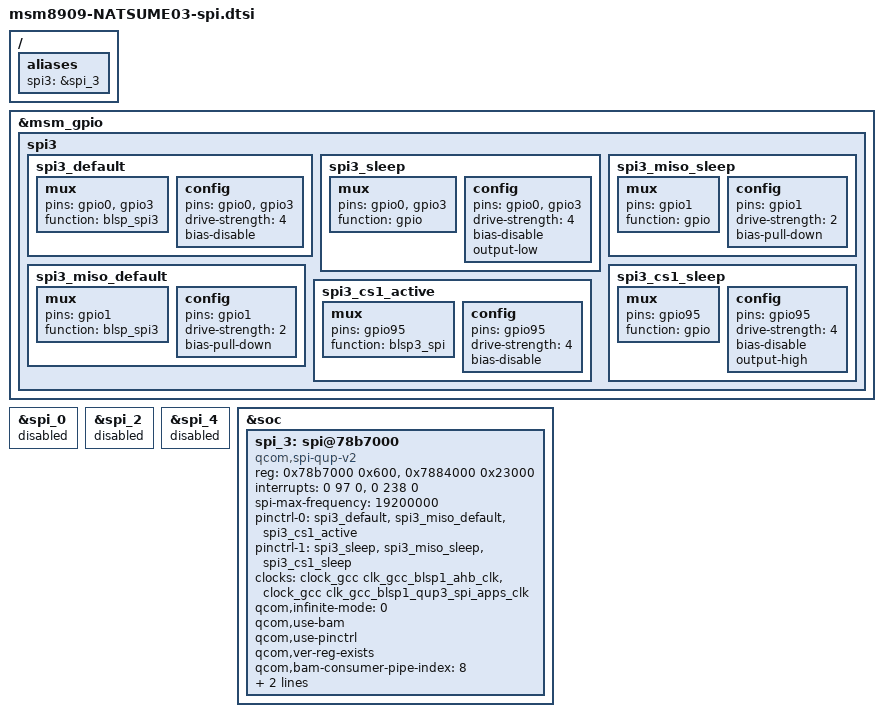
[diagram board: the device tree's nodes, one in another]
/*
 * This software is contributed or developed by KYOCERA Corporation.
 * (C) 2019 KYOCERA Corporation
 *
 * This program is free software; you can redistribute it and/or modify
 * it under the terms of the GNU General Public License version 2 and
 * only version 2 as published by the Free Software Foundation.
 *
 * This program is distributed in the hope that it will be useful,
 * but WITHOUT ANY WARRANTY; without even the implied warranty of
 * MERCHANTABILITY or FITNESS FOR A PARTICULAR PURPOSE.  See the
 * GNU General Public License for more details.
 */

&msm_gpio {
    /delete-node/ spi3;
    spi3 {
        spi3_default: spi3_default {
            mux {
                pins = "gpio0", "gpio3";
                function = "blsp_spi3";
            };
            config {
                pins = "gpio0", "gpio3";
                drive-strength = <4>;
                bias-disable; /* No PULL */
            };
        };
        spi3_sleep: spi3_sleep {
            mux {
                pins = "gpio0", "gpio3";
                function = "gpio";
            };
            config {
                pins = "gpio0", "gpio3";
                drive-strength = <4>;
                bias-disable; /* No PULL */
                output-low;
            };
        };
        spi3_miso_default: spi3_miso_default {
            mux {
                pins = "gpio1";
                function = "blsp_spi3";
            };
            config {
                pins = "gpio1";
                drive-strength = <2>;
                bias-pull-down;
            };
        };
        spi3_miso_sleep: spi3_miso_sleep {
            mux {
                pins = "gpio1";
                function = "gpio";
            };
            config {
                pins = "gpio1";
                drive-strength = <2>;
                bias-pull-down;
            };
        };
        spi3_cs1_active: spi3_cs1_active {
            mux {
                pins = "gpio95";
                function = "blsp3_spi";
            };
            config {
                pins = "gpio95";
                drive-strength = <4>;
                bias-disable;
            };
        };
        spi3_cs1_sleep: spi3_cs1_sleep {
            mux {
                pins = "gpio95";
                function = "gpio";
            };
            config {
                pins = "gpio95";
                drive-strength = <4>;
                bias-disable;
                output-high;
            };
        };
    };
};

/ {
    aliases {
        spi3 = &spi_3;
    };
};

&spi_0 {
    status = "disabled";
};

&spi_2 {
    status = "disabled";
};

&spi_4 {
    status = "disabled";
};

&soc {
    spi_3: spi@78b7000 {
        compatible = "qcom,spi-qup-v2";
        #address-cells = <1>;
        #size-cells = <0>;
        reg-names = "spi_physical", "spi_bam_physical";
        reg = <0x78b7000 0x600>,
              <0x7884000 0x23000>;
        interrupt-names = "spi_irq", "spi_bam_irq";
        interrupts = <0 97 0>, <0 238 0>;
        spi-max-frequency = <19200000>;
        pinctrl-names = "spi_default", "spi_sleep";
        pinctrl-0 = <&spi3_default &spi3_miso_default &spi3_cs1_active>;
        pinctrl-1 = <&spi3_sleep &spi3_miso_sleep &spi3_cs1_sleep>;
        clocks = <&clock_gcc clk_gcc_blsp1_ahb_clk>,
                 <&clock_gcc clk_gcc_blsp1_qup3_spi_apps_clk>;
        clock-names = "iface_clk", "core_clk";
        qcom,infinite-mode = <0>;
        qcom,use-bam;
        qcom,use-pinctrl;
        qcom,ver-reg-exists;
        qcom,bam-consumer-pipe-index = <8>;
        qcom,bam-producer-pipe-index = <9>;
        qcom,master-id = <86>;
    };
};


